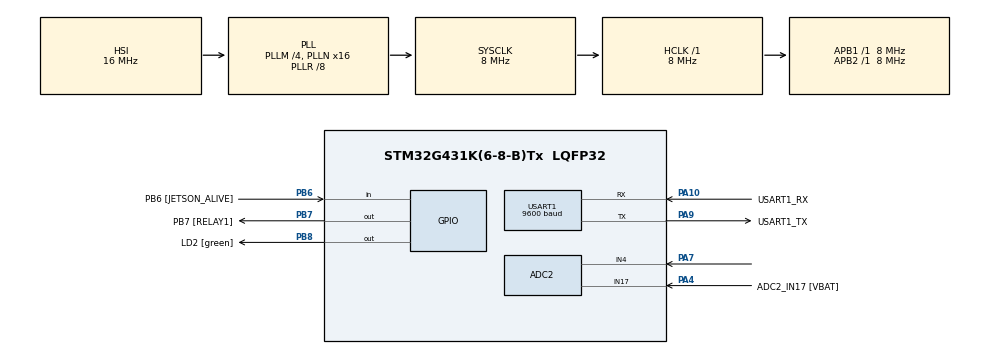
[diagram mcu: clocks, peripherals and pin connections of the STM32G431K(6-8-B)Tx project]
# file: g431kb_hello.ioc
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ADC2.Channel-3\#ChannelRegularConversion=ADC_CHANNEL_4
ADC2.Channel-4\#ChannelRegularConversion=ADC_CHANNEL_17
ADC2.ClockPrescaler=ADC_CLOCK_ASYNC_DIV256
ADC2.DiscontinuousConvMode=ENABLE
ADC2.EOCSelection=ADC_EOC_SINGLE_CONV
ADC2.NbrOfConversion=2
ADC2.NbrOfConversionFlag=1
ADC2.NbrOfDiscConversion=1
ADC2.OffsetNumber-3\#ChannelRegularConversion=ADC_OFFSET_NONE
ADC2.OffsetNumber-4\#ChannelRegularConversion=ADC_OFFSET_NONE
ADC2.Rank-3\#ChannelRegularConversion=1
ADC2.Rank-4\#ChannelRegularConversion=2
ADC2.SamplingTime-3\#ChannelRegularConversion=ADC_SAMPLETIME_640CYCLES_5
ADC2.SamplingTime-4\#ChannelRegularConversion=ADC_SAMPLETIME_640CYCLES_5
Dma.Request0=USART1_TX
Dma.Request1=USART1_RX
Dma.USART1_RX.1.Direction=DMA_PERIPH_TO_MEMORY
Dma.USART1_RX.1.EventEnable=DISABLE
Dma.USART1_RX.1.Instance=DMA1_Channel1
Dma.USART1_RX.1.MemDataAlignment=DMA_MDATAALIGN_BYTE
Dma.USART1_RX.1.MemInc=DMA_MINC_ENABLE
Dma.USART1_RX.1.Mode=DMA_CIRCULAR
Dma.USART1_RX.1.PeriphDataAlignment=DMA_PDATAALIGN_BYTE
Dma.USART1_RX.1.PeriphInc=DMA_PINC_DISABLE
Dma.USART1_RX.1.Polarity=HAL_DMAMUX_REQ_GEN_RISING
Dma.USART1_RX.1.Priority=DMA_PRIORITY_LOW
Dma.USART1_RX.1.RequestNumber=1
Dma.USART1_RX.1.SignalID=NONE
Dma.USART1_RX.1.SyncEnable=DISABLE
Dma.USART1_RX.1.SyncPolarity=HAL_DMAMUX_SYNC_NO_EVENT
Dma.USART1_RX.1.SyncRequestNumber=1
Dma.USART1_RX.1.SyncSignalID=NONE
Dma.USART1_TX.0.Direction=DMA_MEMORY_TO_PERIPH
Dma.USART1_TX.0.EventEnable=DISABLE
Dma.USART1_TX.0.Instance=DMA1_Channel2
Dma.USART1_TX.0.MemDataAlignment=DMA_MDATAALIGN_BYTE
Dma.USART1_TX.0.MemInc=DMA_MINC_ENABLE
Dma.USART1_TX.0.Mode=DMA_NORMAL
Dma.USART1_TX.0.PeriphDataAlignment=DMA_PDATAALIGN_BYTE
Dma.USART1_TX.0.PeriphInc=DMA_PINC_DISABLE
Dma.USART1_TX.0.Polarity=HAL_DMAMUX_REQ_GEN_RISING
Dma.USART1_TX.0.Priority=DMA_PRIORITY_LOW
Dma.USART1_TX.0.RequestNumber=1
Dma.USART1_TX.0.SignalID=NONE
Dma.USART1_TX.0.SyncEnable=DISABLE
Dma.USART1_TX.0.SyncPolarity=HAL_DMAMUX_SYNC_NO_EVENT
Dma.USART1_TX.0.SyncRequestNumber=1
Dma.USART1_TX.0.SyncSignalID=NONE
Mcu.Family=STM32G4
Mcu.Name=STM32G431K(6-8-B)Tx
Mcu.Package=LQFP32
Mcu.UserConstants=CCR1_Val,8000
NVIC.DMA1_Channel1_IRQn=true\:0\:0\:false\:false\:true\:false\:true
NVIC.DMA1_Channel2_IRQn=true\:0\:0\:false\:false\:true\:false\:true
NVIC.PriorityGroup=NVIC_PRIORITYGROUP_4
NVIC.RTC_WKUP_IRQn=true\:0\:0\:false\:false\:true\:true\:true
NVIC.USART1_IRQn=true\:0\:0\:false\:false\:true\:true\:true
PA10.GPIO_Label=USART1_RX
PA10.Mode=Asynchronous
PA10.Signal=USART1_RX
PA13.GPIO_Label=T_SWDIO
PA13.Mode=Serial_Wire
PA13.Signal=SYS_JTMS-SWDIO
PA14.GPIO_Label=T_SWCLK
PA14.Mode=Serial_Wire
PA14.Signal=SYS_JTCK-SWCLK
PA4.GPIO_Label=ADC2_IN17 [VBAT]
PA4.Mode=IN17-Single-Ended
PA4.Signal=ADC2_IN17
PA7.Mode=IN4-Single-Ended
PA7.Signal=ADC2_IN4
PA9.GPIO_Label=USART1_TX
PA9.Mode=Asynchronous
PA9.Signal=USART1_TX
PB3.GPIO_Label=T_SWO
PB3.Signal=SYS_JTDO-SWO
PB6.GPIO_Label=PB6 [JETSON_ALIVE]
PB6.GPIO_PuPd=GPIO_PULLDOWN
PB6.Signal=GPIO_Input
PB7.GPIO_Label=PB7 [RELAY1]
PB7.GPIO_ModeDefaultOutputPP=GPIO_MODE_OUTPUT_PP
PB7.GPIO_PuPd=GPIO_PULLDOWN
PB7.PinState=GPIO_PIN_RESET
PB7.Signal=GPIO_Output
PB8-BOOT0.GPIO_Label=LD2 [green]
PB8-BOOT0.Signal=GPIO_Output
ProjectManager.HeapSize=0x200
ProjectManager.StackSize=0x400
ProjectManager.TargetToolchain=SW4STM32
RCC.ADC12CLockSelection=RCC_ADC12CLKSOURCE_PLL
RCC.ADC12Freq_Value=8000000
RCC.AHBFreq_Value=8000000
RCC.APB1Freq_Value=8000000
RCC.APB1TimFreq_Value=8000000
RCC.APB2Freq_Value=8000000
RCC.APB2TimFreq_Value=8000000
RCC.CortexFreq_Value=8000000
RCC.EXTERNAL_CLOCK_VALUE=12288000
RCC.HCLKFreq_Value=8000000
RCC.HSE_VALUE=8000000
RCC.HSI48_VALUE=48000000
RCC.HSI_VALUE=16000000
RCC.LSE_VALUE=32768
RCC.PLLM=RCC_PLLM_DIV4
RCC.PLLN=16
RCC.PLLP=RCC_PLLP_DIV8
RCC.PLLR=RCC_PLLR_DIV8
RCC.SYSCLKFreq_VALUE=8000000
RCC.SYSCLKSource=RCC_SYSCLKSOURCE_PLLCLK
RCC.USART1CLockSelection=RCC_USART1CLKSOURCE_SYSCLK
RCC.USBFreq_Value=32000000
RCC.VCOOutputFreq_Value=64000000
RTC.WakeUpClock=RTC_WAKEUPCLOCK_CK_SPRE_16BITS
USART1.BaudRate=9600
USART1.DMADisableonRxErrorParam=ADVFEATURE_DMA_ENABLEONRXERROR
USART1.FIFOMode=FIFOMODE_ENABLE
USART1.VirtualMode-Asynchronous=VM_ASYNC
VP_RTC_VS_RTC_Activate.Mode=RTC_Enabled
VP_RTC_VS_RTC_WakeUp_intern.Mode=WakeUp
VP_SYS_VS_DBSignals.Mode=DisableDeadBatterySignals
board=NUCLEO-G431KB

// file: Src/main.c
/* USER CODE BEGIN Header */
/**
  ******************************************************************************
  * @file           : main.c
  * @brief          : Main program body
  ******************************************************************************
  * @attention
  *
  * <h2><center>&copy; Copyright (c) 2020 STMicroelectronics.
  * All rights reserved.</center></h2>
  *
  * This software component is licensed by ST under BSD 3-Clause license,
  * the "License"; You may not use this file except in compliance with the
  * License. You may obtain a copy of the License at:
  *                        opensource.org/licenses/BSD-3-Clause
  *
  ******************************************************************************
  */
/* USER CODE END Header */

#include "main.h"

/* USER CODE BEGIN Includes */
#include "customMain.h"
/* USER CODE END Includes */

ADC_HandleTypeDef hadc2;

RTC_HandleTypeDef hrtc;

UART_HandleTypeDef huart1;
DMA_HandleTypeDef hdma_usart1_tx;
DMA_HandleTypeDef hdma_usart1_rx;

void SystemClock_Config(void);
static void MX_GPIO_Init(void);
static void MX_DMA_Init(void);
static void MX_ADC2_Init(void);
static void MX_USART1_UART_Init(void);
static void MX_RTC_Init(void);

int main(void)
{
  /* USER CODE BEGIN 1 */
  //uint8_t pszData[] = "Hello\r\n\0";
  /* USER CODE END 1 */

  /* MCU Configuration--------------------------------------------------------*/

  /* Reset of all peripherals, Initializes the Flash interface and the Systick. */
  HAL_Init();

  /* Configure the system clock */
  SystemClock_Config();

  /* Initialize all configured peripherals */
  MX_GPIO_Init();
  MX_DMA_Init();
  MX_ADC2_Init();
  MX_USART1_UART_Init();
  MX_RTC_Init();
  /* USER CODE BEGIN 2 */
  customSetup();
  /* USER CODE END 2 */

  /* Infinite loop */
  while (1)
  {

    /* USER CODE BEGIN 3 */
	customLoop();
  }
  /* USER CODE END 3 */
}

void SystemClock_Config(void)
{
  RCC_OscInitTypeDef RCC_OscInitStruct = {0};
  RCC_ClkInitTypeDef RCC_ClkInitStruct = {0};
  RCC_PeriphCLKInitTypeDef PeriphClkInit = {0};

  /** Configure the main internal regulator output voltage
  */
  HAL_PWREx_ControlVoltageScaling(PWR_REGULATOR_VOLTAGE_SCALE1);
  /** Initializes the CPU, AHB and APB busses clocks
  */
  RCC_OscInitStruct.OscillatorType = RCC_OSCILLATORTYPE_HSI|RCC_OSCILLATORTYPE_LSI;
  RCC_OscInitStruct.HSIState = RCC_HSI_ON;
  RCC_OscInitStruct.HSICalibrationValue = RCC_HSICALIBRATION_DEFAULT;
  RCC_OscInitStruct.LSIState = RCC_LSI_ON;
  RCC_OscInitStruct.PLL.PLLState = RCC_PLL_ON;
  RCC_OscInitStruct.PLL.PLLSource = RCC_PLLSOURCE_HSI;
  RCC_OscInitStruct.PLL.PLLM = RCC_PLLM_DIV4;
  RCC_OscInitStruct.PLL.PLLN = 16;
  RCC_OscInitStruct.PLL.PLLP = RCC_PLLP_DIV8;
  RCC_OscInitStruct.PLL.PLLQ = RCC_PLLQ_DIV2;
  RCC_OscInitStruct.PLL.PLLR = RCC_PLLR_DIV8;
  if (HAL_RCC_OscConfig(&RCC_OscInitStruct) != HAL_OK)
  {
    Error_Handler();
  }
  /** Initializes the CPU, AHB and APB busses clocks
  */
  RCC_ClkInitStruct.ClockType = RCC_CLOCKTYPE_HCLK|RCC_CLOCKTYPE_SYSCLK
                              |RCC_CLOCKTYPE_PCLK1|RCC_CLOCKTYPE_PCLK2;
  RCC_ClkInitStruct.SYSCLKSource = RCC_SYSCLKSOURCE_PLLCLK;
  RCC_ClkInitStruct.AHBCLKDivider = RCC_SYSCLK_DIV1;
  RCC_ClkInitStruct.APB1CLKDivider = RCC_HCLK_DIV1;
  RCC_ClkInitStruct.APB2CLKDivider = RCC_HCLK_DIV1;

  if (HAL_RCC_ClockConfig(&RCC_ClkInitStruct, FLASH_LATENCY_0) != HAL_OK)
  {
    Error_Handler();
  }
  /** Initializes the peripherals clocks
  */
  PeriphClkInit.PeriphClockSelection = RCC_PERIPHCLK_RTC|RCC_PERIPHCLK_USART1
                              |RCC_PERIPHCLK_ADC12;
  PeriphClkInit.Usart1ClockSelection = RCC_USART1CLKSOURCE_SYSCLK;
  PeriphClkInit.Adc12ClockSelection = RCC_ADC12CLKSOURCE_PLL;
  PeriphClkInit.RTCClockSelection = RCC_RTCCLKSOURCE_LSI;

  if (HAL_RCCEx_PeriphCLKConfig(&PeriphClkInit) != HAL_OK)
  {
    Error_Handler();
  }
}

static void MX_ADC2_Init(void)
{

  ADC_ChannelConfTypeDef sConfig = {0};

  /** Common config
  */
  hadc2.Instance = ADC2;
  hadc2.Init.ClockPrescaler = ADC_CLOCK_ASYNC_DIV256;
  hadc2.Init.Resolution = ADC_RESOLUTION_12B;
  hadc2.Init.DataAlign = ADC_DATAALIGN_RIGHT;
  hadc2.Init.GainCompensation = 0;
  hadc2.Init.ScanConvMode = ADC_SCAN_ENABLE;
  hadc2.Init.EOCSelection = ADC_EOC_SINGLE_CONV;
  hadc2.Init.LowPowerAutoWait = DISABLE;
  hadc2.Init.ContinuousConvMode = DISABLE;
  hadc2.Init.NbrOfConversion = 2;
  hadc2.Init.DiscontinuousConvMode = ENABLE;
  hadc2.Init.NbrOfDiscConversion = 1;
  hadc2.Init.ExternalTrigConv = ADC_SOFTWARE_START;
  hadc2.Init.ExternalTrigConvEdge = ADC_EXTERNALTRIGCONVEDGE_NONE;
  hadc2.Init.DMAContinuousRequests = DISABLE;
  hadc2.Init.Overrun = ADC_OVR_DATA_PRESERVED;
  hadc2.Init.OversamplingMode = DISABLE;
  if (HAL_ADC_Init(&hadc2) != HAL_OK)
  {
    Error_Handler();
  }
  /** Configure Regular Channel
  */
  sConfig.Channel = ADC_CHANNEL_4;
  sConfig.Rank = ADC_REGULAR_RANK_1;
  sConfig.SamplingTime = ADC_SAMPLETIME_640CYCLES_5;
  sConfig.SingleDiff = ADC_SINGLE_ENDED;
  sConfig.OffsetNumber = ADC_OFFSET_NONE;
  sConfig.Offset = 0;
  if (HAL_ADC_ConfigChannel(&hadc2, &sConfig) != HAL_OK)
  {
    Error_Handler();
  }
  /** Configure Regular Channel
  */
  sConfig.Channel = ADC_CHANNEL_17;
  sConfig.Rank = ADC_REGULAR_RANK_2;
  if (HAL_ADC_ConfigChannel(&hadc2, &sConfig) != HAL_OK)
  {
    Error_Handler();
  }

}

static void MX_RTC_Init(void)
{

  /** Initialize RTC Only
  */
  hrtc.Instance = RTC;
  hrtc.Init.HourFormat = RTC_HOURFORMAT_24;
  hrtc.Init.AsynchPrediv = 127;
  hrtc.Init.SynchPrediv = 255;
  hrtc.Init.OutPut = RTC_OUTPUT_DISABLE;
  hrtc.Init.OutPutRemap = RTC_OUTPUT_REMAP_NONE;
  hrtc.Init.OutPutPullUp = RTC_OUTPUT_PULLUP_NONE;
  if (HAL_RTC_Init(&hrtc) != HAL_OK)
  {
    Error_Handler();
  }
  /** Enable the WakeUp
  */
  if (HAL_RTCEx_SetWakeUpTimer_IT(&hrtc, 0, RTC_WAKEUPCLOCK_CK_SPRE_16BITS) != HAL_OK)
  {
    Error_Handler();
  }

}

static void MX_USART1_UART_Init(void)
{

  huart1.Instance = USART1;
  huart1.Init.BaudRate = 9600;
  huart1.Init.WordLength = UART_WORDLENGTH_8B;
  huart1.Init.StopBits = UART_STOPBITS_1;
  huart1.Init.Parity = UART_PARITY_NONE;
  huart1.Init.Mode = UART_MODE_TX_RX;
  huart1.Init.HwFlowCtl = UART_HWCONTROL_NONE;
  huart1.Init.OverSampling = UART_OVERSAMPLING_16;
  huart1.Init.OneBitSampling = UART_ONE_BIT_SAMPLE_DISABLE;
  huart1.Init.ClockPrescaler = UART_PRESCALER_DIV1;
  huart1.AdvancedInit.AdvFeatureInit = UART_ADVFEATURE_NO_INIT;
  if (HAL_UART_Init(&huart1) != HAL_OK)
  {
    Error_Handler();
  }
  if (HAL_UARTEx_SetTxFifoThreshold(&huart1, UART_TXFIFO_THRESHOLD_1_8) != HAL_OK)
  {
    Error_Handler();
  }
  if (HAL_UARTEx_SetRxFifoThreshold(&huart1, UART_RXFIFO_THRESHOLD_1_8) != HAL_OK)
  {
    Error_Handler();
  }
  if (HAL_UARTEx_EnableFifoMode(&huart1) != HAL_OK)
  {
    Error_Handler();
  }

}

static void MX_DMA_Init(void)
{

  /* DMA controller clock enable */
  __HAL_RCC_DMAMUX1_CLK_ENABLE();
  __HAL_RCC_DMA1_CLK_ENABLE();

  /* DMA interrupt init */
  /* DMA1_Channel1_IRQn interrupt configuration */
  HAL_NVIC_SetPriority(DMA1_Channel1_IRQn, 0, 0);
  HAL_NVIC_EnableIRQ(DMA1_Channel1_IRQn);
  /* DMA1_Channel2_IRQn interrupt configuration */
  HAL_NVIC_SetPriority(DMA1_Channel2_IRQn, 0, 0);
  HAL_NVIC_EnableIRQ(DMA1_Channel2_IRQn);

}

static void MX_GPIO_Init(void)
{
  GPIO_InitTypeDef GPIO_InitStruct = {0};

  /* GPIO Ports Clock Enable */
  __HAL_RCC_GPIOF_CLK_ENABLE();
  __HAL_RCC_GPIOG_CLK_ENABLE();
  __HAL_RCC_GPIOA_CLK_ENABLE();
  __HAL_RCC_GPIOB_CLK_ENABLE();

  /*Configure GPIO pin Output Level */
  HAL_GPIO_WritePin(GPIOB, PB7_Pin|LD2_Pin, GPIO_PIN_RESET);

  /*Configure GPIO pins : PF0 PF1 */
  GPIO_InitStruct.Pin = GPIO_PIN_0|GPIO_PIN_1;
  GPIO_InitStruct.Mode = GPIO_MODE_ANALOG;
  GPIO_InitStruct.Pull = GPIO_NOPULL;
  HAL_GPIO_Init(GPIOF, &GPIO_InitStruct);

  /*Configure GPIO pin : PG10 */
  GPIO_InitStruct.Pin = GPIO_PIN_10;
  GPIO_InitStruct.Mode = GPIO_MODE_ANALOG;
  GPIO_InitStruct.Pull = GPIO_NOPULL;
  HAL_GPIO_Init(GPIOG, &GPIO_InitStruct);

  /*Configure GPIO pins : PA0 PA1 PA2 PA3
                           PA5 PA6 PA8 PA11
                           PA12 PA15 */
  GPIO_InitStruct.Pin = GPIO_PIN_0|GPIO_PIN_1|GPIO_PIN_2|GPIO_PIN_3
                          |GPIO_PIN_5|GPIO_PIN_6|GPIO_PIN_8|GPIO_PIN_11
                          |GPIO_PIN_12|GPIO_PIN_15;
  GPIO_InitStruct.Mode = GPIO_MODE_ANALOG;
  GPIO_InitStruct.Pull = GPIO_NOPULL;
  HAL_GPIO_Init(GPIOA, &GPIO_InitStruct);

  /*Configure GPIO pins : PB0 PB4 PB5 */
  GPIO_InitStruct.Pin = GPIO_PIN_0|GPIO_PIN_4|GPIO_PIN_5;
  GPIO_InitStruct.Mode = GPIO_MODE_ANALOG;
  GPIO_InitStruct.Pull = GPIO_NOPULL;
  HAL_GPIO_Init(GPIOB, &GPIO_InitStruct);

  /*Configure GPIO pin : PB6_Pin */
  GPIO_InitStruct.Pin = PB6_Pin;
  GPIO_InitStruct.Mode = GPIO_MODE_INPUT;
  GPIO_InitStruct.Pull = GPIO_PULLDOWN;
  HAL_GPIO_Init(PB6_GPIO_Port, &GPIO_InitStruct);

  /*Configure GPIO pin : PB7_Pin */
  GPIO_InitStruct.Pin = PB7_Pin;
  GPIO_InitStruct.Mode = GPIO_MODE_OUTPUT_PP;
  GPIO_InitStruct.Pull = GPIO_PULLDOWN;
  GPIO_InitStruct.Speed = GPIO_SPEED_FREQ_LOW;
  HAL_GPIO_Init(PB7_GPIO_Port, &GPIO_InitStruct);

  /*Configure GPIO pin : LD2_Pin */
  GPIO_InitStruct.Pin = LD2_Pin;
  GPIO_InitStruct.Mode = GPIO_MODE_OUTPUT_PP;
  GPIO_InitStruct.Pull = GPIO_NOPULL;
  GPIO_InitStruct.Speed = GPIO_SPEED_FREQ_LOW;
  HAL_GPIO_Init(LD2_GPIO_Port, &GPIO_InitStruct);

}

void Error_Handler(void)
{
}

/************************ (C) COPYRIGHT STMicroelectronics *****END OF FILE****/
